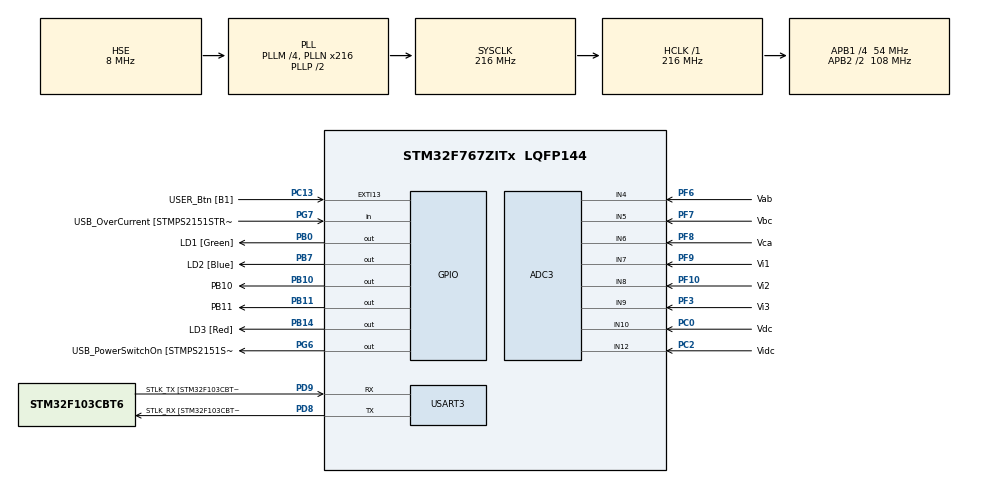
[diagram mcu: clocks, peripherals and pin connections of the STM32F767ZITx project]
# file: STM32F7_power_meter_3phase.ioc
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ADC3.Channel-0\#ChannelRegularConversion=ADC_CHANNEL_4
ADC3.Channel-10\#ChannelRegularConversion=ADC_CHANNEL_12
ADC3.Channel-11\#ChannelRegularConversion=ADC_CHANNEL_10
ADC3.Channel-12\#ChannelRegularConversion=ADC_CHANNEL_12
ADC3.Channel-13\#ChannelRegularConversion=ADC_CHANNEL_10
ADC3.Channel-14\#ChannelRegularConversion=ADC_CHANNEL_12
ADC3.Channel-15\#ChannelRegularConversion=ADC_CHANNEL_10
ADC3.Channel-16\#ChannelRegularConversion=ADC_CHANNEL_12
ADC3.Channel-17\#ChannelRegularConversion=ADC_CHANNEL_10
ADC3.Channel-4\#ChannelRegularConversion=ADC_CHANNEL_5
ADC3.Channel-5\#ChannelRegularConversion=ADC_CHANNEL_6
ADC3.Channel-6\#ChannelRegularConversion=ADC_CHANNEL_7
ADC3.Channel-7\#ChannelRegularConversion=ADC_CHANNEL_8
ADC3.Channel-8\#ChannelRegularConversion=ADC_CHANNEL_9
ADC3.Channel-9\#ChannelRegularConversion=ADC_CHANNEL_10
ADC3.ClockPrescaler=ADC_CLOCK_SYNC_PCLK_DIV6
ADC3.ContinuousConvMode=ENABLE
ADC3.DMAContinuousRequests=ENABLE
ADC3.InjNumberOfConversion=0
ADC3.NbrOfConversion=15
ADC3.NbrOfConversionFlag=1
ADC3.Rank-0\#ChannelRegularConversion=1
ADC3.Rank-10\#ChannelRegularConversion=8
ADC3.Rank-11\#ChannelRegularConversion=9
ADC3.Rank-12\#ChannelRegularConversion=10
ADC3.Rank-13\#ChannelRegularConversion=11
ADC3.Rank-14\#ChannelRegularConversion=12
ADC3.Rank-15\#ChannelRegularConversion=13
ADC3.Rank-16\#ChannelRegularConversion=14
ADC3.Rank-17\#ChannelRegularConversion=15
ADC3.Rank-4\#ChannelRegularConversion=2
ADC3.Rank-5\#ChannelRegularConversion=3
ADC3.Rank-6\#ChannelRegularConversion=4
ADC3.Rank-7\#ChannelRegularConversion=5
ADC3.Rank-8\#ChannelRegularConversion=6
ADC3.Rank-9\#ChannelRegularConversion=7
ADC3.SamplingTime-0\#ChannelRegularConversion=ADC_SAMPLETIME_28CYCLES
ADC3.SamplingTime-10\#ChannelRegularConversion=ADC_SAMPLETIME_28CYCLES
ADC3.SamplingTime-11\#ChannelRegularConversion=ADC_SAMPLETIME_28CYCLES
ADC3.SamplingTime-12\#ChannelRegularConversion=ADC_SAMPLETIME_28CYCLES
ADC3.SamplingTime-13\#ChannelRegularConversion=ADC_SAMPLETIME_28CYCLES
ADC3.SamplingTime-14\#ChannelRegularConversion=ADC_SAMPLETIME_28CYCLES
ADC3.SamplingTime-15\#ChannelRegularConversion=ADC_SAMPLETIME_28CYCLES
ADC3.SamplingTime-16\#ChannelRegularConversion=ADC_SAMPLETIME_28CYCLES
ADC3.SamplingTime-17\#ChannelRegularConversion=ADC_SAMPLETIME_28CYCLES
ADC3.SamplingTime-4\#ChannelRegularConversion=ADC_SAMPLETIME_28CYCLES
ADC3.SamplingTime-5\#ChannelRegularConversion=ADC_SAMPLETIME_28CYCLES
ADC3.SamplingTime-6\#ChannelRegularConversion=ADC_SAMPLETIME_28CYCLES
ADC3.SamplingTime-7\#ChannelRegularConversion=ADC_SAMPLETIME_28CYCLES
ADC3.SamplingTime-8\#ChannelRegularConversion=ADC_SAMPLETIME_28CYCLES
ADC3.SamplingTime-9\#ChannelRegularConversion=ADC_SAMPLETIME_28CYCLES
Dma.ADC3.0.Direction=DMA_PERIPH_TO_MEMORY
Dma.ADC3.0.FIFOMode=DMA_FIFOMODE_DISABLE
Dma.ADC3.0.Instance=DMA2_Stream0
Dma.ADC3.0.MemDataAlignment=DMA_MDATAALIGN_WORD
Dma.ADC3.0.MemInc=DMA_MINC_ENABLE
Dma.ADC3.0.Mode=DMA_CIRCULAR
Dma.ADC3.0.PeriphDataAlignment=DMA_PDATAALIGN_WORD
Dma.ADC3.0.PeriphInc=DMA_PINC_DISABLE
Dma.ADC3.0.Priority=DMA_PRIORITY_LOW
Dma.Request0=ADC3
Mcu.Family=STM32F7
Mcu.Name=STM32F767ZITx
Mcu.Package=LQFP144
NVIC.DMA2_Stream0_IRQn=true\:0\:0\:false\:false\:true\:false\:true
NVIC.PriorityGroup=NVIC_PRIORITYGROUP_4
NVIC.TIM6_DAC_IRQn=true\:0\:0\:false\:false\:true\:true\:true
NVIC.TIM7_IRQn=true\:0\:0\:false\:false\:true\:true\:true
PA1.GPIO_Label=RMII_REF_CLK [LAN8742A-CZ-TR_REFCLK0]
PA1.Signal=ETH_REF_CLK
PA10.GPIO_Label=USB_ID
PA10.Signal=USB_OTG_FS_ID
PA11.GPIO_Label=USB_DM
PA11.Signal=USB_OTG_FS_DM
PA12.GPIO_Label=USB_DP
PA12.Signal=USB_OTG_FS_DP
PA13.GPIO_Label=TMS
PA13.Mode=Serial_Wire
PA13.Signal=SYS_JTMS-SWDIO
PA14.GPIO_Label=TCK
PA14.Mode=Serial_Wire
PA14.Signal=SYS_JTCK-SWCLK
PA2.GPIO_Label=RMII_MDIO [LAN8742A-CZ-TR_MDIO]
PA2.Signal=ETH_MDIO
PA7.GPIO_Label=RMII_CRS_DV [LAN8742A-CZ-TR_CRS_DV]
PA7.Signal=ETH_CRS_DV
PA8.GPIO_Label=USB_SOF [TP1]
PA8.Signal=USB_OTG_FS_SOF
PA9.GPIO_Label=USB_VBUS
PA9.Signal=USB_OTG_FS_VBUS
PB0.GPIO_Label=LD1 [Green]
PB0.Signal=GPIO_Output
PB10.GPIO_Label=PB10
PB10.Signal=GPIO_Output
PB11.GPIO_Label=PB11
PB11.Signal=GPIO_Output
PB13.GPIO_Label=RMII_TXD1 [LAN8742A-CZ-TR_TXD1]
PB13.Signal=ETH_TXD1
PB14.GPIO_Label=LD3 [Red]
PB14.Signal=GPIO_Output
PB3.GPIO_Label=SWO
PB3.Signal=SYS_JTDO-SWO
PB7.GPIO_Label=LD2 [Blue]
PB7.Signal=GPIO_Output
PC0.GPIO_Label=Vdc
PC0.Signal=ADCx_IN10
PC1.GPIO_Label=RMII_MDC [LAN8742A-CZ-TR_MDC]
PC1.Signal=ETH_MDC
PC13.GPIO_Label=USER_Btn [B1]
PC13.Signal=GPXTI13
PC14/OSC32_IN.Mode=LSE-External-Oscillator
PC14/OSC32_IN.Signal=RCC_OSC32_IN
PC15/OSC32_OUT.Mode=LSE-External-Oscillator
PC15/OSC32_OUT.Signal=RCC_OSC32_OUT
PC2.GPIO_Label=Vidc
PC2.Signal=ADCx_IN12
PC4.GPIO_Label=RMII_RXD0 [LAN8742A-CZ-TR_RXD0]
PC4.Signal=ETH_RXD0
PC5.GPIO_Label=RMII_RXD1 [LAN8742A-CZ-TR_RXD1]
PC5.Signal=ETH_RXD1
PD15.Signal=S_TIM4_CH4
PD8.GPIO_Label=STLK_RX [STM32F103CBT6_PA3]
PD8.Mode=Asynchronous
PD8.Signal=USART3_TX
PD9.GPIO_Label=STLK_TX [STM32F103CBT6_PA2]
PD9.Mode=Asynchronous
PD9.Signal=USART3_RX
PF10.GPIO_Label=Vi2
PF10.Mode=IN8
PF10.Signal=ADC3_IN8
PF3.GPIO_Label=Vi3
PF3.Mode=IN9
PF3.Signal=ADC3_IN9
PF6.GPIO_Label=Vab
PF6.Mode=IN4
PF6.Signal=ADC3_IN4
PF7.GPIO_Label=Vbc
PF7.Mode=IN5
PF7.Signal=ADC3_IN5
PF8.GPIO_Label=Vca
PF8.Mode=IN6
PF8.Signal=ADC3_IN6
PF9.GPIO_Label=Vi1
PF9.Mode=IN7
PF9.Signal=ADC3_IN7
PG11.GPIO_Label=RMII_TX_EN [LAN8742A-CZ-TR_TXEN]
PG11.Signal=ETH_TX_EN
PG13.GPIO_Label=RMII_TXD0 [LAN8742A-CZ-TR_TXD0]
PG13.Signal=ETH_TXD0
PG6.GPIO_Label=USB_PowerSwitchOn [STMPS2151STR_EN]
PG6.Signal=GPIO_Output
PG7.GPIO_Label=USB_OverCurrent [STMPS2151STR_FAULT]
PG7.Signal=GPIO_Input
PH0/OSC_IN.GPIO_Label=MCO [STM32F103CBT6_PA8]
PH0/OSC_IN.Mode=HSE-External-Clock-Source
PH0/OSC_IN.Signal=RCC_OSC_IN
PH1/OSC_OUT.Mode=HSE-External-Clock-Source
PH1/OSC_OUT.Signal=RCC_OSC_OUT
ProjectManager.HeapSize=0x200
ProjectManager.StackSize=0x400
ProjectManager.TargetToolchain=STM32CubeIDE
RCC.48MHZClocksFreq_Value=24000000
RCC.AHBFreq_Value=216000000
RCC.APB1CLKDivider=RCC_HCLK_DIV4
RCC.APB1Freq_Value=54000000
RCC.APB1TimFreq_Value=108000000
RCC.APB2CLKDivider=RCC_HCLK_DIV2
RCC.APB2Freq_Value=108000000
RCC.APB2TimFreq_Value=216000000
RCC.CortexFreq_Value=216000000
RCC.HCLKFreq_Value=216000000
RCC.HSE_VALUE=8000000
RCC.HSI_VALUE=16000000
RCC.PLLM=4
RCC.PLLMUL=RCC_PLL_MUL9
RCC.PLLN=216
RCC.PLLQ=9
RCC.PLLSourceVirtual=RCC_PLLSOURCE_HSE
RCC.PRESCALERUSB=RCC_USBCLKSOURCE_PLL_DIV1_5
RCC.SYSCLKFreq_VALUE=216000000
RCC.SYSCLKSource=RCC_SYSCLKSOURCE_PLLCLK
RCC.SYSCLKSourceVirtual=RCC_SYSCLKSOURCE_PLLCLK
RCC.USBFreq_Value=48000000
RCC.VCOOutputFreq_Value=432000000
SH.ADCx_IN10.0=ADC3_IN10,IN10
SH.ADCx_IN12.0=ADC3_IN12,IN12
SH.S_TIM4_CH4.0=TIM4_CH4
TIM6.AutoReloadPreload=TIM_AUTORELOAD_PRELOAD_ENABLE
TIM6.TIM_MasterOutputTrigger=TIM_TRGO_UPDATE
USART3.VirtualMode-Asynchronous=VM_ASYNC
VP_TIM6_VS_ClockSourceINT.Mode=Enable_Timer
VP_TIM7_VS_ClockSourceINT.Mode=Enable_Timer
board=NUCLEO-F767ZI

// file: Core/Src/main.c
/* USER CODE BEGIN Header */
/**
  ******************************************************************************
  * @file           : main.c
  * @brief          : Main program body
  ******************************************************************************
  * @attention
  *
  * <h2><center>&copy; Copyright (c) 2021 STMicroelectronics.
  * All rights reserved.</center></h2>
  *
  * This software component is licensed by ST under BSD 3-Clause license,
  * the "License"; You may not use this file except in compliance with the
  * License. You may obtain a copy of the License at:
  *                        opensource.org/licenses/BSD-3-Clause
  *
  ******************************************************************************
  */
/* USER CODE END Header */
#include "main.h"

/* USER CODE BEGIN Includes */
#include "adc.h"

/* USER CODE END Includes */

ADC_HandleTypeDef hadc3;
DMA_HandleTypeDef hdma_adc3;

TIM_HandleTypeDef htim6;
TIM_HandleTypeDef htim7;

UART_HandleTypeDef huart3;

void SystemClock_Config(void);
static void MX_GPIO_Init(void);
static void MX_DMA_Init(void);
static void MX_ADC3_Init(void);
static void MX_USART3_UART_Init(void);
static void MX_TIM6_Init(void);
static void MX_TIM7_Init(void);

int main(void)
{

  /* MCU Configuration--------------------------------------------------------*/

  /* Reset of all peripherals, Initializes the Flash interface and the Systick. */
  HAL_Init();

  /* Configure the system clock */
  SystemClock_Config();

  /* Initialize all configured peripherals */
  MX_GPIO_Init();
  MX_DMA_Init();
  MX_ADC3_Init();
  MX_USART3_UART_Init();
  MX_TIM6_Init();
  MX_TIM7_Init();
  /* USER CODE BEGIN 2 */

  vADCStartSampling();
//  HAL_GPIO_WritePin(LD1_GPIO_Port, LD1_Pin, GPIO_PIN_SET);

  /* USER CODE END 2 */

  /* Infinite loop */
  while (1)
  {

  }
}

void SystemClock_Config(void)
{
  RCC_OscInitTypeDef RCC_OscInitStruct = {0};
  RCC_ClkInitTypeDef RCC_ClkInitStruct = {0};
  RCC_PeriphCLKInitTypeDef PeriphClkInitStruct = {0};

  /** Configure LSE Drive Capability
  */
  HAL_PWR_EnableBkUpAccess();
  /** Configure the main internal regulator output voltage
  */
  __HAL_RCC_PWR_CLK_ENABLE();
  __HAL_PWR_VOLTAGESCALING_CONFIG(PWR_REGULATOR_VOLTAGE_SCALE1);
  /** Initializes the RCC Oscillators according to the specified parameters
  * in the RCC_OscInitTypeDef structure.
  */
  RCC_OscInitStruct.OscillatorType = RCC_OSCILLATORTYPE_HSE;
  RCC_OscInitStruct.HSEState = RCC_HSE_BYPASS;
  RCC_OscInitStruct.PLL.PLLState = RCC_PLL_ON;
  RCC_OscInitStruct.PLL.PLLSource = RCC_PLLSOURCE_HSE;
  RCC_OscInitStruct.PLL.PLLM = 4;
  RCC_OscInitStruct.PLL.PLLN = 216;
  RCC_OscInitStruct.PLL.PLLP = RCC_PLLP_DIV2;
  RCC_OscInitStruct.PLL.PLLQ = 9;
  if (HAL_RCC_OscConfig(&RCC_OscInitStruct) != HAL_OK)
  {
    Error_Handler();
  }
  /** Activate the Over-Drive mode
  */
  if (HAL_PWREx_EnableOverDrive() != HAL_OK)
  {
    Error_Handler();
  }
  /** Initializes the CPU, AHB and APB buses clocks
  */
  RCC_ClkInitStruct.ClockType = RCC_CLOCKTYPE_HCLK|RCC_CLOCKTYPE_SYSCLK
                              |RCC_CLOCKTYPE_PCLK1|RCC_CLOCKTYPE_PCLK2;
  RCC_ClkInitStruct.SYSCLKSource = RCC_SYSCLKSOURCE_PLLCLK;
  RCC_ClkInitStruct.AHBCLKDivider = RCC_SYSCLK_DIV1;
  RCC_ClkInitStruct.APB1CLKDivider = RCC_HCLK_DIV4;
  RCC_ClkInitStruct.APB2CLKDivider = RCC_HCLK_DIV2;

  if (HAL_RCC_ClockConfig(&RCC_ClkInitStruct, FLASH_LATENCY_7) != HAL_OK)
  {
    Error_Handler();
  }
  PeriphClkInitStruct.PeriphClockSelection = RCC_PERIPHCLK_USART3;
  PeriphClkInitStruct.Usart3ClockSelection = RCC_USART3CLKSOURCE_PCLK1;
  if (HAL_RCCEx_PeriphCLKConfig(&PeriphClkInitStruct) != HAL_OK)
  {
    Error_Handler();
  }
}

static void MX_ADC3_Init(void)
{

  ADC_ChannelConfTypeDef sConfig = {0};

  /** Configure the global features of the ADC (Clock, Resolution, Data Alignment and number of conversion)
  */
  hadc3.Instance = ADC3;
  hadc3.Init.ClockPrescaler = ADC_CLOCK_SYNC_PCLK_DIV6;
  hadc3.Init.Resolution = ADC_RESOLUTION_12B;
  hadc3.Init.ScanConvMode = ADC_SCAN_ENABLE;
  hadc3.Init.ContinuousConvMode = ENABLE;
  hadc3.Init.DiscontinuousConvMode = DISABLE;
  hadc3.Init.ExternalTrigConvEdge = ADC_EXTERNALTRIGCONVEDGE_NONE;
  hadc3.Init.ExternalTrigConv = ADC_SOFTWARE_START;
  hadc3.Init.DataAlign = ADC_DATAALIGN_RIGHT;
  hadc3.Init.NbrOfConversion = 15;
  hadc3.Init.DMAContinuousRequests = ENABLE;
  hadc3.Init.EOCSelection = ADC_EOC_SINGLE_CONV;
  if (HAL_ADC_Init(&hadc3) != HAL_OK)
  {
    Error_Handler();
  }
  /** Configure for the selected ADC regular channel its corresponding rank in the sequencer and its sample time.
  */
  sConfig.Channel = ADC_CHANNEL_4;
  sConfig.Rank = ADC_REGULAR_RANK_1;
  sConfig.SamplingTime = ADC_SAMPLETIME_28CYCLES;
  if (HAL_ADC_ConfigChannel(&hadc3, &sConfig) != HAL_OK)
  {
    Error_Handler();
  }
  /** Configure for the selected ADC regular channel its corresponding rank in the sequencer and its sample time.
  */
  sConfig.Channel = ADC_CHANNEL_5;
  sConfig.Rank = ADC_REGULAR_RANK_2;
  if (HAL_ADC_ConfigChannel(&hadc3, &sConfig) != HAL_OK)
  {
    Error_Handler();
  }
  /** Configure for the selected ADC regular channel its corresponding rank in the sequencer and its sample time.
  */
  sConfig.Channel = ADC_CHANNEL_6;
  sConfig.Rank = ADC_REGULAR_RANK_3;
  if (HAL_ADC_ConfigChannel(&hadc3, &sConfig) != HAL_OK)
  {
    Error_Handler();
  }
  /** Configure for the selected ADC regular channel its corresponding rank in the sequencer and its sample time.
  */
  sConfig.Channel = ADC_CHANNEL_7;
  sConfig.Rank = ADC_REGULAR_RANK_4;
  if (HAL_ADC_ConfigChannel(&hadc3, &sConfig) != HAL_OK)
  {
    Error_Handler();
  }
  /** Configure for the selected ADC regular channel its corresponding rank in the sequencer and its sample time.
  */
  sConfig.Channel = ADC_CHANNEL_8;
  sConfig.Rank = ADC_REGULAR_RANK_5;
  if (HAL_ADC_ConfigChannel(&hadc3, &sConfig) != HAL_OK)
  {
    Error_Handler();
  }
  /** Configure for the selected ADC regular channel its corresponding rank in the sequencer and its sample time.
  */
  sConfig.Channel = ADC_CHANNEL_9;
  sConfig.Rank = ADC_REGULAR_RANK_6;
  if (HAL_ADC_ConfigChannel(&hadc3, &sConfig) != HAL_OK)
  {
    Error_Handler();
  }
  /** Configure for the selected ADC regular channel its corresponding rank in the sequencer and its sample time.
  */
  sConfig.Channel = ADC_CHANNEL_10;
  sConfig.Rank = ADC_REGULAR_RANK_7;
  if (HAL_ADC_ConfigChannel(&hadc3, &sConfig) != HAL_OK)
  {
    Error_Handler();
  }
  /** Configure for the selected ADC regular channel its corresponding rank in the sequencer and its sample time.
  */
  sConfig.Channel = ADC_CHANNEL_12;
  sConfig.Rank = ADC_REGULAR_RANK_8;
  if (HAL_ADC_ConfigChannel(&hadc3, &sConfig) != HAL_OK)
  {
    Error_Handler();
  }
  /** Configure for the selected ADC regular channel its corresponding rank in the sequencer and its sample time.
  */
  sConfig.Channel = ADC_CHANNEL_10;
  sConfig.Rank = ADC_REGULAR_RANK_9;
  if (HAL_ADC_ConfigChannel(&hadc3, &sConfig) != HAL_OK)
  {
    Error_Handler();
  }
  /** Configure for the selected ADC regular channel its corresponding rank in the sequencer and its sample time.
  */
  sConfig.Channel = ADC_CHANNEL_12;
  sConfig.Rank = ADC_REGULAR_RANK_10;
  if (HAL_ADC_ConfigChannel(&hadc3, &sConfig) != HAL_OK)
  {
    Error_Handler();
  }
  /** Configure for the selected ADC regular channel its corresponding rank in the sequencer and its sample time.
  */
  sConfig.Channel = ADC_CHANNEL_10;
  sConfig.Rank = ADC_REGULAR_RANK_11;
  if (HAL_ADC_ConfigChannel(&hadc3, &sConfig) != HAL_OK)
  {
    Error_Handler();
  }
  /** Configure for the selected ADC regular channel its corresponding rank in the sequencer and its sample time.
  */
  sConfig.Channel = ADC_CHANNEL_12;
  sConfig.Rank = ADC_REGULAR_RANK_12;
  if (HAL_ADC_ConfigChannel(&hadc3, &sConfig) != HAL_OK)
  {
    Error_Handler();
  }
  /** Configure for the selected ADC regular channel its corresponding rank in the sequencer and its sample time.
  */
  sConfig.Channel = ADC_CHANNEL_10;
  sConfig.Rank = ADC_REGULAR_RANK_13;
  if (HAL_ADC_ConfigChannel(&hadc3, &sConfig) != HAL_OK)
  {
    Error_Handler();
  }
  /** Configure for the selected ADC regular channel its corresponding rank in the sequencer and its sample time.
  */
  sConfig.Channel = ADC_CHANNEL_12;
  sConfig.Rank = ADC_REGULAR_RANK_14;
  if (HAL_ADC_ConfigChannel(&hadc3, &sConfig) != HAL_OK)
  {
    Error_Handler();
  }
  /** Configure for the selected ADC regular channel its corresponding rank in the sequencer and its sample time.
  */
  sConfig.Channel = ADC_CHANNEL_10;
  sConfig.Rank = ADC_REGULAR_RANK_15;
  if (HAL_ADC_ConfigChannel(&hadc3, &sConfig) != HAL_OK)
  {
    Error_Handler();
  }

}

static void MX_TIM6_Init(void)
{

  /* USER CODE BEGIN TIM6_Init 0 */

	//  htim6.Init.Prescaler = (2 * HAL_RCC_GetPCLK1Freq() / 1000000) - 1
	//  htim6.Init.CounterMode = TIM_COUNTERMODE_UP;
	//  htim6.Init.Period = 2 - 1;
	//	each interrupt = 2 us => count 50 times to sample ADC

  /* USER CODE END TIM6_Init 0 */

  TIM_MasterConfigTypeDef sMasterConfig = {0};

  htim6.Instance = TIM6;
  htim6.Init.Prescaler = 0;
  htim6.Init.CounterMode = TIM_COUNTERMODE_UP;
  htim6.Init.Period = 65535;
  htim6.Init.AutoReloadPreload = TIM_AUTORELOAD_PRELOAD_ENABLE;
  if (HAL_TIM_Base_Init(&htim6) != HAL_OK)
  {
    Error_Handler();
  }
  sMasterConfig.MasterOutputTrigger = TIM_TRGO_UPDATE;
  sMasterConfig.MasterSlaveMode = TIM_MASTERSLAVEMODE_DISABLE;
  if (HAL_TIMEx_MasterConfigSynchronization(&htim6, &sMasterConfig) != HAL_OK)
  {
    Error_Handler();
  }

}

static void MX_TIM7_Init(void)
{

  TIM_MasterConfigTypeDef sMasterConfig = {0};

  /* USER CODE BEGIN TIM7_Init 1 */

//  htim7.Init.Prescaler = (2 * HAL_RCC_GetPCLK1Freq() / 1000000) - 1;
//  htim7.Init.CounterMode = TIM_COUNTERMODE_UP;
//  htim7.Init.Period = 2 - 1;
//	each interrupt = 2 us => count 50 times to sample ADC

  htim7.Init.Prescaler = (2 * HAL_RCC_GetPCLK1Freq() / 1000000) - 1;
  htim7.Init.CounterMode = TIM_COUNTERMODE_UP;
  htim7.Init.Period = SAMPLING_TIME - 1;

  /* USER CODE END TIM7_Init 1 */
  htim7.Instance = TIM7;
  htim7.Init.Prescaler = 0;
  htim7.Init.CounterMode = TIM_COUNTERMODE_UP;
  htim7.Init.Period = 65535;
  htim7.Init.AutoReloadPreload = TIM_AUTORELOAD_PRELOAD_DISABLE;
  if (HAL_TIM_Base_Init(&htim7) != HAL_OK)
  {
    Error_Handler();
  }
  sMasterConfig.MasterOutputTrigger = TIM_TRGO_RESET;
  sMasterConfig.MasterSlaveMode = TIM_MASTERSLAVEMODE_DISABLE;
  if (HAL_TIMEx_MasterConfigSynchronization(&htim7, &sMasterConfig) != HAL_OK)
  {
    Error_Handler();
  }

}

static void MX_USART3_UART_Init(void)
{

  huart3.Instance = USART3;
  huart3.Init.BaudRate = 115200;
  huart3.Init.WordLength = UART_WORDLENGTH_8B;
  huart3.Init.StopBits = UART_STOPBITS_1;
  huart3.Init.Parity = UART_PARITY_NONE;
  huart3.Init.Mode = UART_MODE_TX_RX;
  huart3.Init.HwFlowCtl = UART_HWCONTROL_NONE;
  huart3.Init.OverSampling = UART_OVERSAMPLING_16;
  huart3.Init.OneBitSampling = UART_ONE_BIT_SAMPLE_DISABLE;
  huart3.AdvancedInit.AdvFeatureInit = UART_ADVFEATURE_NO_INIT;
  if (HAL_UART_Init(&huart3) != HAL_OK)
  {
    Error_Handler();
  }

}

static void MX_DMA_Init(void)
{

  /* DMA controller clock enable */
  __HAL_RCC_DMA2_CLK_ENABLE();

  /* DMA interrupt init */
  /* DMA2_Stream0_IRQn interrupt configuration */
  HAL_NVIC_SetPriority(DMA2_Stream0_IRQn, 0, 0);
  HAL_NVIC_EnableIRQ(DMA2_Stream0_IRQn);

}

static void MX_GPIO_Init(void)
{
  GPIO_InitTypeDef GPIO_InitStruct = {0};

  /* GPIO Ports Clock Enable */
  __HAL_RCC_GPIOC_CLK_ENABLE();
  __HAL_RCC_GPIOF_CLK_ENABLE();
  __HAL_RCC_GPIOH_CLK_ENABLE();
  __HAL_RCC_GPIOA_CLK_ENABLE();
  __HAL_RCC_GPIOB_CLK_ENABLE();
  __HAL_RCC_GPIOD_CLK_ENABLE();
  __HAL_RCC_GPIOG_CLK_ENABLE();

  /*Configure GPIO pin Output Level */
  HAL_GPIO_WritePin(GPIOB, LD1_Pin|PB10_Pin|PB11_Pin|LD3_Pin
                          |LD2_Pin, GPIO_PIN_RESET);

  /*Configure GPIO pin Output Level */
  HAL_GPIO_WritePin(USB_PowerSwitchOn_GPIO_Port, USB_PowerSwitchOn_Pin, GPIO_PIN_RESET);

  /*Configure GPIO pin : USER_Btn_Pin */
  GPIO_InitStruct.Pin = USER_Btn_Pin;
  GPIO_InitStruct.Mode = GPIO_MODE_IT_RISING;
  GPIO_InitStruct.Pull = GPIO_NOPULL;
  HAL_GPIO_Init(USER_Btn_GPIO_Port, &GPIO_InitStruct);

  /*Configure GPIO pins : RMII_MDC_Pin RMII_RXD0_Pin RMII_RXD1_Pin */
  GPIO_InitStruct.Pin = RMII_MDC_Pin|RMII_RXD0_Pin|RMII_RXD1_Pin;
  GPIO_InitStruct.Mode = GPIO_MODE_AF_PP;
  GPIO_InitStruct.Pull = GPIO_NOPULL;
  GPIO_InitStruct.Speed = GPIO_SPEED_FREQ_VERY_HIGH;
  GPIO_InitStruct.Alternate = GPIO_AF11_ETH;
  HAL_GPIO_Init(GPIOC, &GPIO_InitStruct);

  /*Configure GPIO pins : RMII_REF_CLK_Pin RMII_MDIO_Pin RMII_CRS_DV_Pin */
  GPIO_InitStruct.Pin = RMII_REF_CLK_Pin|RMII_MDIO_Pin|RMII_CRS_DV_Pin;
  GPIO_InitStruct.Mode = GPIO_MODE_AF_PP;
  GPIO_InitStruct.Pull = GPIO_NOPULL;
  GPIO_InitStruct.Speed = GPIO_SPEED_FREQ_VERY_HIGH;
  GPIO_InitStruct.Alternate = GPIO_AF11_ETH;
  HAL_GPIO_Init(GPIOA, &GPIO_InitStruct);

  /*Configure GPIO pins : LD1_Pin PB10_Pin PB11_Pin LD3_Pin
                           LD2_Pin */
  GPIO_InitStruct.Pin = LD1_Pin|PB10_Pin|PB11_Pin|LD3_Pin
                          |LD2_Pin;
  GPIO_InitStruct.Mode = GPIO_MODE_OUTPUT_PP;
  GPIO_InitStruct.Pull = GPIO_NOPULL;
  GPIO_InitStruct.Speed = GPIO_SPEED_FREQ_LOW;
  HAL_GPIO_Init(GPIOB, &GPIO_InitStruct);

  /*Configure GPIO pin : RMII_TXD1_Pin */
  GPIO_InitStruct.Pin = RMII_TXD1_Pin;
  GPIO_InitStruct.Mode = GPIO_MODE_AF_PP;
  GPIO_InitStruct.Pull = GPIO_NOPULL;
  GPIO_InitStruct.Speed = GPIO_SPEED_FREQ_VERY_HIGH;
  GPIO_InitStruct.Alternate = GPIO_AF11_ETH;
  HAL_GPIO_Init(RMII_TXD1_GPIO_Port, &GPIO_InitStruct);

  /*Configure GPIO pin : USB_PowerSwitchOn_Pin */
  GPIO_InitStruct.Pin = USB_PowerSwitchOn_Pin;
  GPIO_InitStruct.Mode = GPIO_MODE_OUTPUT_PP;
  GPIO_InitStruct.Pull = GPIO_NOPULL;
  GPIO_InitStruct.Speed = GPIO_SPEED_FREQ_LOW;
  HAL_GPIO_Init(USB_PowerSwitchOn_GPIO_Port, &GPIO_InitStruct);

  /*Configure GPIO pin : USB_OverCurrent_Pin */
  GPIO_InitStruct.Pin = USB_OverCurrent_Pin;
  GPIO_InitStruct.Mode = GPIO_MODE_INPUT;
  GPIO_InitStruct.Pull = GPIO_NOPULL;
  HAL_GPIO_Init(USB_OverCurrent_GPIO_Port, &GPIO_InitStruct);

  /*Configure GPIO pins : USB_SOF_Pin USB_ID_Pin USB_DM_Pin USB_DP_Pin */
  GPIO_InitStruct.Pin = USB_SOF_Pin|USB_ID_Pin|USB_DM_Pin|USB_DP_Pin;
  GPIO_InitStruct.Mode = GPIO_MODE_AF_PP;
  GPIO_InitStruct.Pull = GPIO_NOPULL;
  GPIO_InitStruct.Speed = GPIO_SPEED_FREQ_VERY_HIGH;
  GPIO_InitStruct.Alternate = GPIO_AF10_OTG_FS;
  HAL_GPIO_Init(GPIOA, &GPIO_InitStruct);

  /*Configure GPIO pin : USB_VBUS_Pin */
  GPIO_InitStruct.Pin = USB_VBUS_Pin;
  GPIO_InitStruct.Mode = GPIO_MODE_INPUT;
  GPIO_InitStruct.Pull = GPIO_NOPULL;
  HAL_GPIO_Init(USB_VBUS_GPIO_Port, &GPIO_InitStruct);

  /*Configure GPIO pins : RMII_TX_EN_Pin RMII_TXD0_Pin */
  GPIO_InitStruct.Pin = RMII_TX_EN_Pin|RMII_TXD0_Pin;
  GPIO_InitStruct.Mode = GPIO_MODE_AF_PP;
  GPIO_InitStruct.Pull = GPIO_NOPULL;
  GPIO_InitStruct.Speed = GPIO_SPEED_FREQ_VERY_HIGH;
  GPIO_InitStruct.Alternate = GPIO_AF11_ETH;
  HAL_GPIO_Init(GPIOG, &GPIO_InitStruct);

}

void Error_Handler(void)
{
  __disable_irq();
  while (1)
  {
  }
}

/************************ (C) COPYRIGHT STMicroelectronics *****END OF FILE****/
